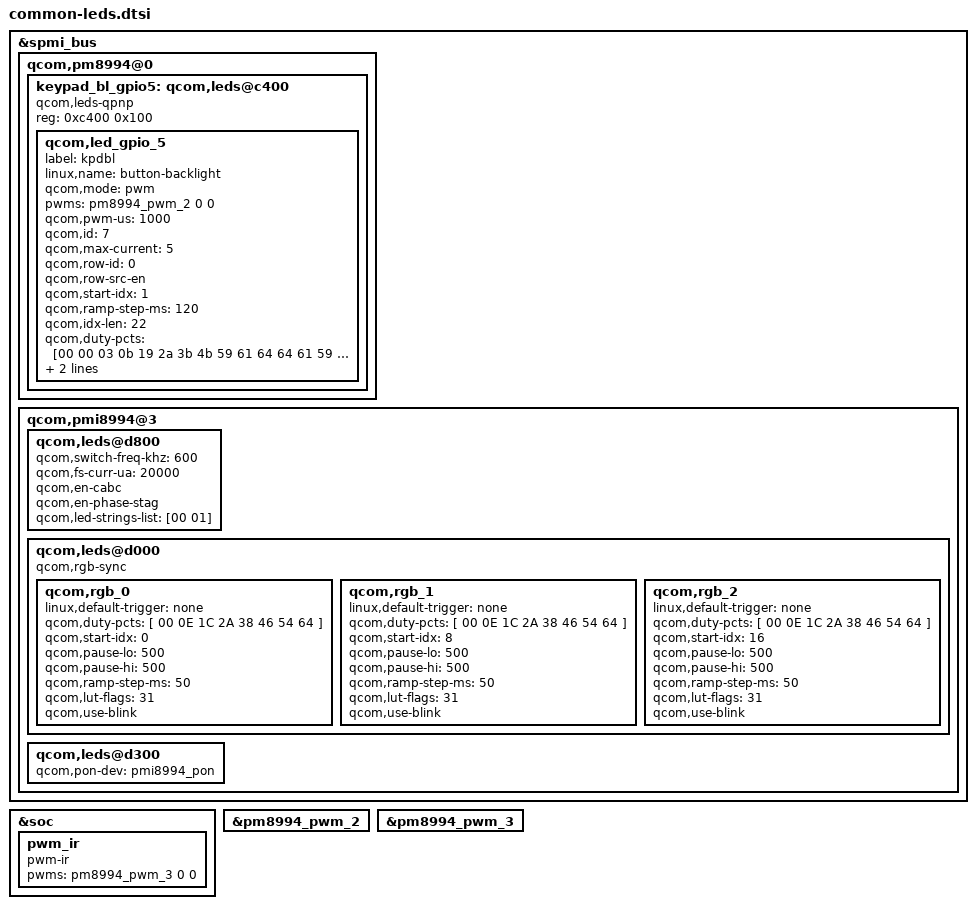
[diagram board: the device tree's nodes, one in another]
/* Copyright (c) 2017, The Linux Foundation. All rights reserved.
 *
 * This program is free software; you can redistribute it and/or modify
 * it under the terms of the GNU General Public License version 2 and
 * only version 2 as published by the Free Software Foundation.
 *
 * This program is distributed in the hope that it will be useful,
 * but WITHOUT ANY WARRANTY; without even the implied warranty of
 * MERCHANTABILITY or FITNESS FOR A PARTICULAR PURPOSE.  See the
 * GNU General Public License for more details.
 */

&spmi_bus {
    qcom,pm8994@0 {
        keypad_bl_gpio5: qcom,leds@c400 {
			compatible = "qcom,leds-qpnp";
			reg = <0xc400 0x100>;
			status = "okay";
			qcom,led_gpio_5 {
				label = "kpdbl";
				linux,name = "button-backlight";
				qcom,mode = "pwm";
				pwms = <&pm8994_pwm_2 0 0>;
				qcom,pwm-us = <1000>;
				qcom,id = <7>;
				qcom,max-current = <5>;
				qcom,row-id = <0>;
				qcom,row-src-en;
				qcom,start-idx = <1>;
				qcom,ramp-step-ms = <120>;
				qcom,idx-len = <22>;
				qcom,duty-pcts = [00
						00 03 0b 19 2a
						3b 4b 59 61 64
						64 61 59 4b 3b
						2a 19 0b 03 00
						00];
				qcom,use-blink;
				qcom,in-order-command-processing;
			};
		};
	};

	qcom,pmi8994@3 {
		qcom,leds@d800 {
			qcom,switch-freq-khz = <600>;
			qcom,fs-curr-ua = <20000>;
			qcom,en-cabc;
			qcom,en-phase-stag;
			qcom,led-strings-list = [00 01];
		};

		qcom,leds@d000 {
			qcom,rgb-sync;

			qcom,rgb_0 {
				linux,default-trigger = "none";
				qcom,duty-pcts = [ 00 0E 1C 2A 38 46 54 64 ];
				qcom,start-idx = <0>;
				qcom,pause-lo = <500>;
				qcom,pause-hi = <500>;
				qcom,ramp-step-ms = <50>;
				qcom,lut-flags = <31>; /* loop, ramp up, reverse, pause hi, pause lo */
				qcom,use-blink;
			};

			qcom,rgb_1 {
				linux,default-trigger = "none";
				qcom,duty-pcts = [ 00 0E 1C 2A 38 46 54 64 ];
				qcom,start-idx = <8>;
				qcom,pause-lo = <500>;
				qcom,pause-hi = <500>;
				qcom,ramp-step-ms = <50>;
				qcom,lut-flags = <31>; /* loop, ramp up, reverse, pause hi, pause lo */
				qcom,use-blink;
			};

			qcom,rgb_2 {
				linux,default-trigger = "none";
				qcom,duty-pcts = [ 00 0E 1C 2A 38 46 54 64 ];
				qcom,start-idx = <16>;
				qcom,pause-lo = <500>;
				qcom,pause-hi = <500>;
				qcom,ramp-step-ms = <50>;
				qcom,lut-flags = <31>; /* loop, ramp up, reverse, pause hi, pause lo */
				qcom,use-blink;
			};
		};

		qcom,leds@d300 {
			qcom,pon-dev = <&pmi8994_pon>;
		};
	};
};

&soc {
	pwm_ir {
		compatible = "pwm-ir";
		pwms = <&pm8994_pwm_3 0 0>;
	};
};

&pm8994_pwm_2 {
	status = "okay";
};

&pm8994_pwm_3 {
	status = "okay";
};
